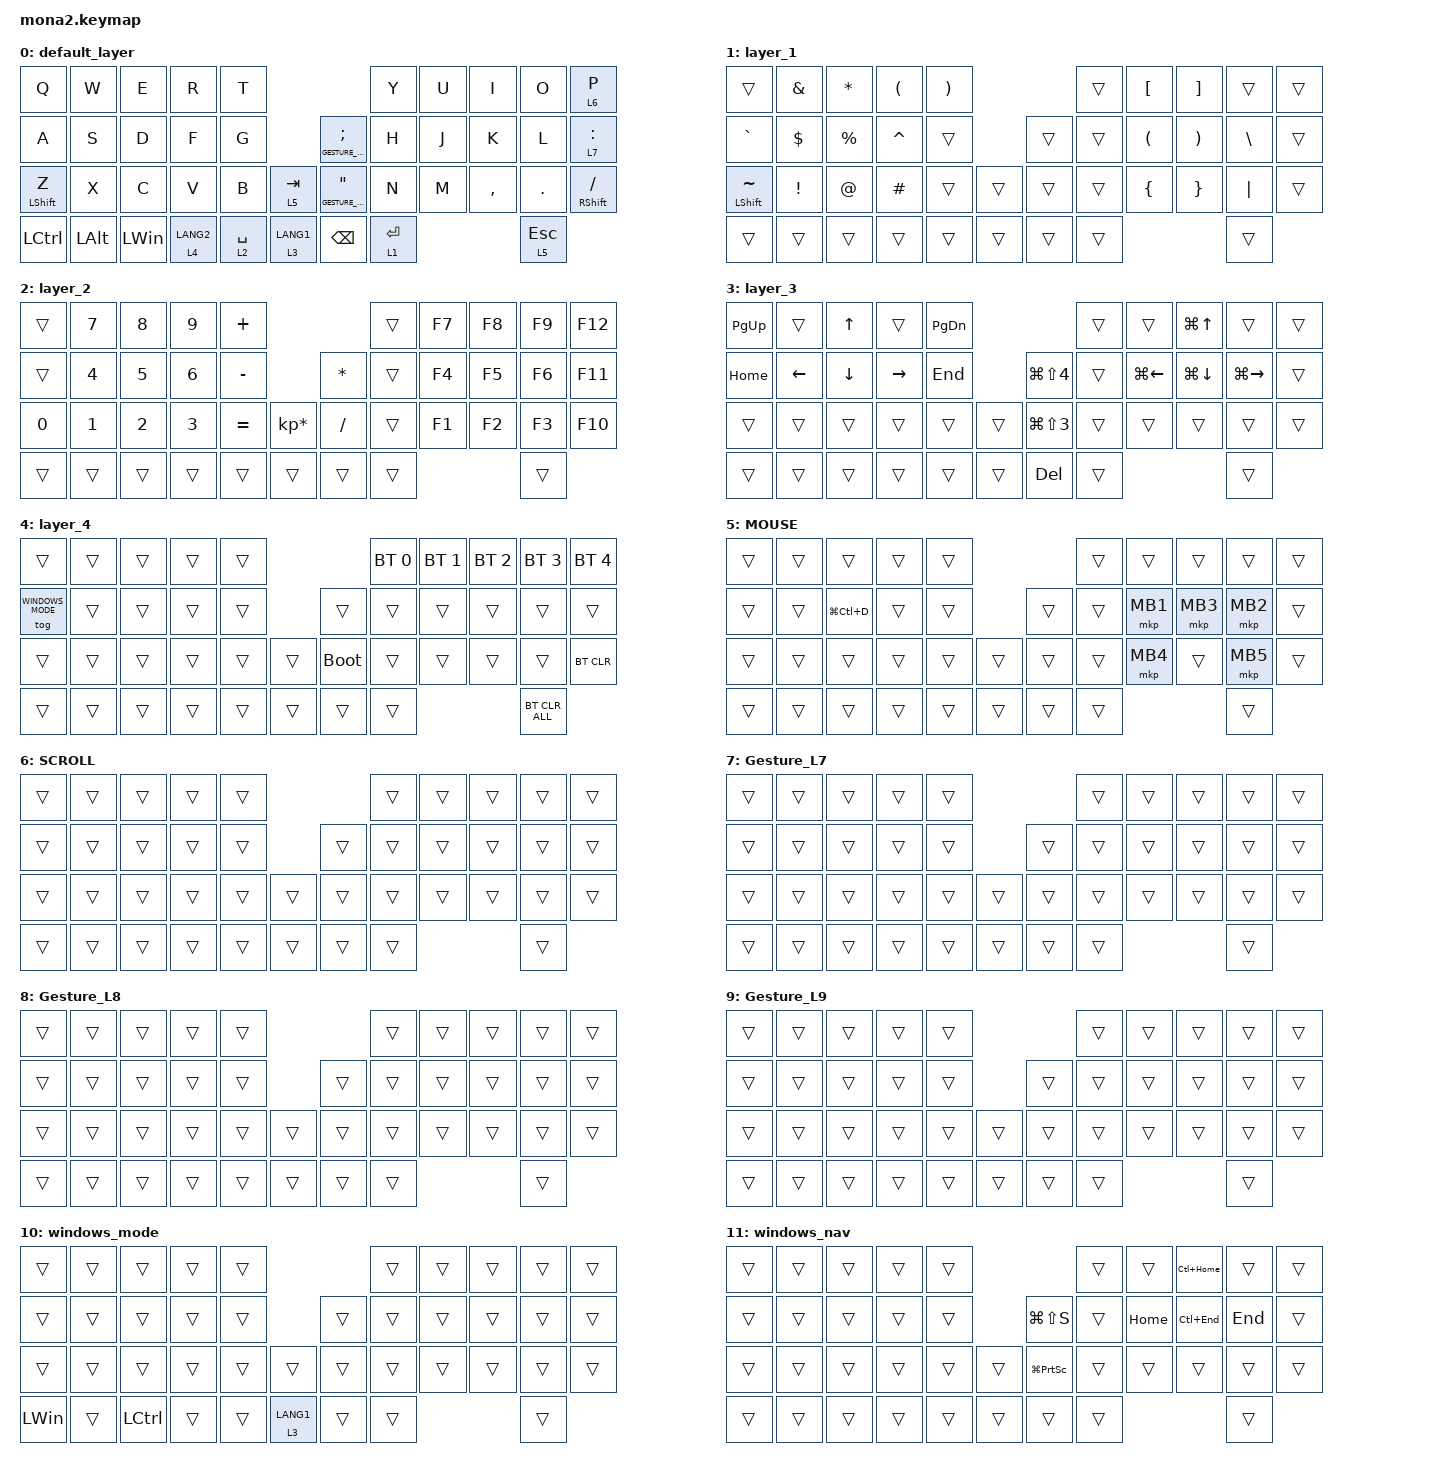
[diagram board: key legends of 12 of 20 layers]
#include <behaviors.dtsi>
#include <dt-bindings/zmk/bt.h>
#include <dt-bindings/zmk/keys.h>
#include <dt-bindings/zmk/pointing.h>
#include "gesture/gesture_L7.dtsi"
#include "gesture/gesture_L8.dtsi"
#include "gesture/gesture_L9.dtsi"
#include "gesture/gesture_L12.dtsi"
#include "gesture/gesture_L13.dtsi"

#define ZMK_POINTING_DEFAULT_SCRL_VAL 100
#define MOUSE 5
#define WINDOWS_MODE 10
#define WINDOWS_NAV 11
#define GESTURE_HISTORY 12
#define GESTURE_DIA 13
#define WINDOWS_TABS 14
#define WINDOWS_DESKTOPS 15
#define WINDOWS_WINDOWS 16
#define WINDOWS_HISTORY 17
#define WINDOWS_DIA 18
#define WINDOWS_MOUSE 19

&mt {
    flavor = "balanced";
    quick-tap-ms = <0>;
};

&lt {
    quick-tap-ms = <200>;
    flavor = "balanced";
};

/ {
    // The navigation overrides only activate while Windows mode and layer 3 are active.
    conditional_layers {
        compatible = "zmk,conditional-layers";

        windows_navigation {
            if-layers = <3 WINDOWS_MODE>;
            then-layer = <WINDOWS_NAV>;
        };

        windows_tabs {
            if-layers = <7 WINDOWS_MODE>;
            then-layer = <WINDOWS_TABS>;
        };

        windows_desktops {
            if-layers = <8 WINDOWS_MODE>;
            then-layer = <WINDOWS_DESKTOPS>;
        };

        windows_windows {
            if-layers = <9 WINDOWS_MODE>;
            then-layer = <WINDOWS_WINDOWS>;
        };

        windows_history {
            if-layers = <GESTURE_HISTORY WINDOWS_MODE>;
            then-layer = <WINDOWS_HISTORY>;
        };

        windows_dia {
            if-layers = <GESTURE_DIA WINDOWS_MODE>;
            then-layer = <WINDOWS_DIA>;
        };

        windows_mouse {
            if-layers = <MOUSE WINDOWS_MODE>;
            then-layer = <WINDOWS_MOUSE>;
        };
    };

    combos {
        compatible = "zmk,combos";

        Gesture_L8 {
            bindings = <&lt 8 LG(TAB)>;
            key-positions = <8 9>;
            layers = <0 MOUSE>;
        };

        Gesture_L8_Windows {
            bindings = <&lt 8 LA(TAB)>;
            key-positions = <8 9>;
            layers = <WINDOWS_MODE WINDOWS_MOUSE>;
        };

        Gesture_L9 {
            bindings = <&lt 9 LEFT_WIN>;
            key-positions = <19 20>;
            layers = <0 MOUSE WINDOWS_MODE WINDOWS_MOUSE>;
        };

        a {
            bindings = <&none>;
            key-positions = <17 29 18 19 31 10 21>;
        };
    };

    macros {
        to_layer_0: to_layer_0 {
            compatible = "zmk,behavior-macro-one-param";
            #binding-cells = <1>;
            bindings = <&to 0 &macro_param_1to1 &kp MACRO_PLACEHOLDER>;
            label = "TO_LAYER_0";
        };

        exit_AML: exit_AML {
            compatible = "zmk,behavior-macro";
            wait-ms = <0>;
            tap-ms = <0>;
            #binding-cells = <0>;
            bindings = <&tog_off MOUSE>;
            label = "exit_AML";
        };

        kp_exit_AML: kp_exit_AML {
            compatible = "zmk,behavior-macro-one-param";
            wait-ms = <0>;
            tap-ms = <0>;
            #binding-cells = <1>;
            bindings = <&macro_param_1to1 &kp MACRO_PLACEHOLDER &exit_AML>;
            label = "KP_exit_AML";
        };
    };

    behaviors {
        lt_to_layer_0: lt_to_layer_0 {
            compatible = "zmk,behavior-hold-tap";
            label = "LAYER_TAP_TO_0";
            #binding-cells = <2>;
            tapping-term-ms = <200>;
            bindings = <&mo>, <&to_layer_0>;
        };

        scroll_up_down: mouse_wheel_up_down {
            compatible = "zmk,behavior-sensor-rotate";
            #sensor-binding-cells = <0>;
            tap-ms = <20>;
            bindings = <&msc SCRL_DOWN>, <&msc SCRL_UP>;
        };

        scroll_right_left: mouse_wheel_right_left {
            compatible = "zmk,behavior-sensor-rotate";
            #sensor-binding-cells = <0>;
            tap-ms = <20>;
            bindings = <&msc SCRL_LEFT>, <&msc SCRL_RIGHT>;
        };

        tog_off: toggle_layer_off {
            compatible = "zmk,behavior-toggle-layer";
            #binding-cells = <1>;
            display-name = "Toggle Layer Off";
            toggle-mode = "off";
        };

        mt_exit_AML_on_tap: mt_exit_AML_on_tap {
            compatible = "zmk,behavior-hold-tap";
            label = "MT_exit_AML_ON_TAP";
            bindings = <&kp>, <&kp_exit_AML>;

            #binding-cells = <2>;
            tapping-term-ms = <200>;
            flavor = "balanced";
            quick-tap-ms = <200>;
        };
    };

    keymap {
        compatible = "zmk,keymap";

        default_layer {
            bindings = <
&kp Q                             &kp W         &kp E         &kp R        &kp T                                                     &kp Y        &kp U  &kp I      &kp O    &lt 6 P
&kp A                             &kp S         &kp D         &kp F        &kp G                                  &lt GESTURE_HISTORY SEMICOLON  &kp H        &kp J  &kp K      &kp L    &lt 7 COLON
&mt_exit_AML_on_tap LEFT_SHIFT Z  &kp X         &kp C         &kp V        &kp B        &lt 5 TAB                 &lt GESTURE_DIA DOUBLE_QUOTES  &kp N        &kp M  &kp COMMA  &kp DOT  &mt RIGHT_SHIFT SLASH
&kp LCTRL                         &kp LEFT_ALT  &kp LEFT_WIN  &lt 4 LANG2  &lt 2 SPACE  &lt_to_layer_0 3 LANG1    &kp BACKSPACE      &lt 1 ENTER                             &lt 5 ESCAPE
            >;

            sensor-bindings = <&scroll_up_down>;
        };

        layer_1 {
            bindings = <
&trans           &kp AMPERSAND  &kp ASTRK    &kp LEFT_PARENTHESIS  &kp RIGHT_PARENTHESIS                    &trans  &kp LEFT_BRACKET      &kp RIGHT_BRACKET      &trans         &trans
&kp GRAVE        &kp DOLLAR     &kp PERCENT  &kp CARET             &trans                           &trans  &trans  &kp LEFT_PARENTHESIS  &kp RIGHT_PARENTHESIS  &kp BACKSLASH  &trans
&mt LSHFT TILDE  &kp EXCL       &kp AT       &kp HASH              &trans                 &trans    &trans  &trans  &kp LEFT_BRACE        &kp RIGHT_BRACE        &kp PIPE       &trans
&trans           &trans         &trans       &trans                &trans                 &trans    &trans  &trans                                                              &trans
            >;

            sensor-bindings = <&scroll_right_left>;
        };

        layer_2 {
            bindings = <
&trans  &kp N7  &kp N8  &kp N9  &kp PLUS                                 &trans  &kp F7  &kp F8  &kp F9  &kp F12
&trans  &kp N4  &kp N5  &kp N6  &kp MINUS                     &kp ASTRK  &trans  &kp F4  &kp F5  &kp F6  &kp F11
&kp N0  &kp N1  &kp N2  &kp N3  &kp EQUAL  &kp KP_MULTIPLY    &kp SLASH  &trans  &kp F1  &kp F2  &kp F3  &kp F10
&trans  &trans  &trans  &trans  &trans     &trans             &trans     &trans                          &trans
            >;

            sensor-bindings = <&scroll_up_down>;
        };

        layer_3 {
            bindings = <
&kp PAGE_UP  &trans    &kp UP_ARROW  &trans           &kp PAGE_DOWN                                     &trans  &trans              &kp LG(UP_ARROW)    &trans               &trans
&kp HOME     &kp LEFT  &kp DOWN      &kp RIGHT_ARROW  &kp END                  &kp LG(LS(N4))  &trans  &kp LG(LEFT_ARROW)  &kp LG(DOWN_ARROW)  &kp LG(RIGHT_ARROW)  &trans
&trans       &trans    &trans        &trans           &trans         &trans    &kp LG(LS(N3))      &trans  &trans              &trans              &trans               &trans
&trans       &trans    &trans        &trans           &trans         &trans    &kp DEL                  &trans                                                               &trans
            >;

            sensor-bindings = <&inc_dec_kp LC(TAB) LC(LS(TAB))>;
        };

        layer_4 {
            bindings = <
&trans  &trans  &trans  &trans  &trans                         &bt BT_SEL 0  &bt BT_SEL 1  &bt BT_SEL 2  &bt BT_SEL 3  &bt BT_SEL 4
&tog WINDOWS_MODE  &trans  &trans  &trans  &trans  &trans  &trans  &trans  &trans  &trans  &trans
&trans  &trans  &trans  &trans  &trans  &trans    &bootloader  &trans        &trans        &trans        &trans        &bt BT_CLR
&trans  &trans  &trans  &trans  &trans  &trans    &trans       &trans                                                  &bt BT_CLR_ALL
            >;

            sensor-bindings = <&scroll_up_down>;
        };

        MOUSE {
            bindings = <
&trans  &trans  &trans  &trans  &trans                    &trans  &trans    &trans    &trans    &trans
&trans  &trans  &kp LG(LC(D))  &trans  &trans            &trans  &trans  &mkp MB1  &mkp MB3  &mkp MB2  &trans
&trans  &trans  &trans  &trans  &trans  &trans    &trans  &trans  &mkp MB4  &trans    &mkp MB5  &trans
&trans  &trans  &trans  &trans  &trans  &trans    &trans  &trans                                &trans
            >;

            sensor-bindings = <&scroll_up_down>;
        };

        SCROLL {
            bindings = <
&trans  &trans  &trans  &trans  &trans                    &trans  &trans  &trans  &trans  &trans
&trans  &trans  &trans  &trans  &trans            &trans  &trans  &trans  &trans  &trans  &trans
&trans  &trans  &trans  &trans  &trans  &trans    &trans  &trans  &trans  &trans  &trans  &trans
&trans  &trans  &trans  &trans  &trans  &trans    &trans  &trans                          &trans
            >;

            sensor-bindings = <&scroll_up_down>;
        };

        Gesture_L7 {
            bindings = <
&trans  &trans  &trans  &trans  &trans                    &trans  &trans  &trans  &trans  &trans
&trans  &trans  &trans  &trans  &trans            &trans  &trans  &trans  &trans  &trans  &trans
&trans  &trans  &trans  &trans  &trans  &trans    &trans  &trans  &trans  &trans  &trans  &trans
&trans  &trans  &trans  &trans  &trans  &trans    &trans  &trans                          &trans
            >;
        };

        Gesture_L8 {
            bindings = <
&trans  &trans  &trans  &trans  &trans                    &trans  &trans  &trans  &trans  &trans
&trans  &trans  &trans  &trans  &trans            &trans  &trans  &trans  &trans  &trans  &trans
&trans  &trans  &trans  &trans  &trans  &trans    &trans  &trans  &trans  &trans  &trans  &trans
&trans  &trans  &trans  &trans  &trans  &trans    &trans  &trans                          &trans
            >;
        };

        Gesture_L9 {
            bindings = <
&trans  &trans  &trans  &trans  &trans                    &trans  &trans  &trans  &trans  &trans
&trans  &trans  &trans  &trans  &trans            &trans  &trans  &trans  &trans  &trans  &trans
&trans  &trans  &trans  &trans  &trans  &trans    &trans  &trans  &trans  &trans  &trans  &trans
&trans  &trans  &trans  &trans  &trans  &trans    &trans  &trans                          &trans
            >;
        };

        // Toggle with layer 4 (hold LANG2) + A. This layer never changes Shift,
        // letters, trackball controls, or access to the existing layer keys.
        windows_mode {
            bindings = <
                &trans  &trans  &trans  &trans  &trans  &trans  &trans  &trans  &trans  &trans
                &trans  &trans  &trans  &trans  &trans  &trans  &trans  &trans  &trans  &trans  &trans
                &trans  &trans  &trans  &trans  &trans  &trans  &trans  &trans  &trans  &trans  &trans  &trans
                &kp LEFT_WIN  &trans  &kp LCTRL  &trans  &trans  &lt 3 LANG1  &trans  &trans  &trans
            >;
        };

        // Only active when both windows_mode and layer_3 are active.
        // Keeps the navigation layer's Mac-style movements on Windows.
        windows_nav {
            bindings = <
                &trans  &trans  &trans  &trans  &trans  &trans  &trans  &kp LC(HOME)  &trans  &trans
                &trans  &trans  &trans  &trans  &trans  &kp LG(LS(S))  &trans  &kp HOME  &kp LC(END)  &kp END  &trans
                &trans  &trans  &trans  &trans  &trans  &trans  &kp LG(PRINTSCREEN)  &trans  &trans  &trans  &trans  &trans
                &trans  &trans  &trans  &trans  &trans  &trans  &trans  &trans  &trans
            >;
        };

        gesture_history {
            bindings = <
                &trans  &trans  &trans  &trans  &trans  &trans  &trans  &trans  &trans  &trans
                &trans  &trans  &trans  &trans  &trans  &trans  &trans  &trans  &trans  &trans  &trans
                &trans  &trans  &trans  &trans  &trans  &trans  &trans  &trans  &trans  &trans  &trans  &trans
                &trans  &trans  &trans  &trans  &trans  &trans  &trans  &trans  &trans
            >;
        };

        gesture_dia {
            bindings = <
                &trans  &trans  &trans  &trans  &trans  &trans  &trans  &trans  &trans  &trans
                &trans  &trans  &trans  &trans  &trans  &trans  &trans  &trans  &trans  &trans  &trans
                &trans  &trans  &trans  &trans  &trans  &trans  &trans  &trans  &trans  &trans  &trans  &trans
                &trans  &trans  &trans  &trans  &trans  &trans  &trans  &trans  &trans
            >;
        };

        windows_tabs {
            bindings = <
                &trans  &trans  &trans  &trans  &trans  &trans  &trans  &trans  &trans  &trans
                &trans  &trans  &trans  &trans  &trans  &trans  &trans  &trans  &trans  &trans  &trans
                &trans  &trans  &trans  &trans  &trans  &trans  &trans  &trans  &trans  &trans  &trans  &trans
                &trans  &trans  &trans  &trans  &trans  &trans  &trans  &trans  &trans
            >;
        };

        windows_desktops {
            bindings = <
                &trans  &trans  &trans  &trans  &trans  &trans  &trans  &trans  &trans  &trans
                &trans  &trans  &trans  &trans  &trans  &trans  &trans  &trans  &trans  &trans  &trans
                &trans  &trans  &trans  &trans  &trans  &trans  &trans  &trans  &trans  &trans  &trans  &trans
                &trans  &trans  &trans  &trans  &trans  &trans  &trans  &trans  &trans
            >;
        };

        windows_windows {
            bindings = <
                &trans  &trans  &trans  &trans  &trans  &trans  &trans  &trans  &trans  &trans
                &trans  &trans  &trans  &trans  &trans  &trans  &trans  &trans  &trans  &trans  &trans
                &trans  &trans  &trans  &trans  &trans  &trans  &trans  &trans  &trans  &trans  &trans  &trans
                &trans  &trans  &trans  &trans  &trans  &trans  &trans  &trans  &trans
            >;
        };

        windows_history {
            bindings = <
                &trans  &trans  &trans  &trans  &trans  &trans  &trans  &trans  &trans  &trans
                &trans  &trans  &trans  &trans  &trans  &trans  &trans  &trans  &trans  &trans  &trans
                &trans  &trans  &trans  &trans  &trans  &trans  &trans  &trans  &trans  &trans  &trans  &trans
                &trans  &trans  &trans  &trans  &trans  &trans  &trans  &trans  &trans
            >;
        };

        windows_dia {
            bindings = <
                &trans  &trans  &trans  &trans  &trans  &trans  &trans  &trans  &trans  &trans
                &trans  &trans  &trans  &trans  &trans  &trans  &trans  &trans  &trans  &trans  &trans
                &trans  &trans  &trans  &trans  &trans  &trans  &trans  &trans  &trans  &trans  &trans  &trans
                &trans  &trans  &trans  &trans  &trans  &trans  &trans  &trans  &trans
            >;
        };

        windows_mouse {
            bindings = <
                &trans  &trans  &trans  &trans  &trans  &trans  &trans  &trans  &trans  &trans
                &trans  &trans  &kp D  &trans  &trans  &trans  &trans  &trans  &trans  &trans  &trans
                &trans  &trans  &trans  &trans  &trans  &trans  &trans  &trans  &trans  &trans  &trans  &trans
                &trans  &trans  &trans  &trans  &trans  &trans  &trans  &trans  &trans
            >;
        };
    };
};
